# EFR32FG25A221F1920IM56 register map
Vendor: Silicon Labs; Series: EFR32; File version: B
Registers are 32-bit, read-write, reset 0x0 unless marked. A register's access mark holds for its fields unless they carry their own. Offsets are from the block's base; [hi:lo] are bit positions; {n}, {i} and the like mark numbered series; 'fields as' and 'values as' point back to an identical list.

## BUFC_NS — BUFC_NS Registers
Base 0x52000000
Same registers: BUFC_S 0x42000000
0x00 IPVERSION ro reset 0x3
0x04 EN
  [0] EN — Enable peripheral clock to this module
0x08 LPMODE
  [1:0] LPEN — Low power mode enable
{0xC+0x40*i} BUF{i}_CTRL (i=0..3)
  [2:0] SIZE — Buffer Size
    0=Sets Buffer size to 64 bytes; 1=Sets Buffer size to 128 bytes; 2=Sets Buffer size to 256 bytes; 3=Sets Buffer size to 512 bytes; 4=Sets Buffer size to 1024 bytes; 5=Sets Buffer size to 2048 bytes; 6=Sets Buffer size to 4096 bytes
{0x10+0x40*i} BUF{i}_ADDR reset 0x20000000 (i=0..3)
  [31:2] ADDR — Buffer Address
{0x14+0x40*i} BUF{i}_WRITEOFFSET (i=0..3)
  [12:0] WRITEOFFSET
{0x18+0x40*i} BUF{i}_READOFFSET (i=0..3)
  [12:0] READOFFSET
{0x20+0x40*i} BUF{i}_READDATA ro (i=0..3)
  [7:0] READDATA — Buffer Read Data
{0x24+0x40*i} BUF{i}_WRITEDATA wo (i=0..3)
  [7:0] WRITEDATA — Buffer Write Data
{0x28+0x40*i} BUF{i}_XWRITE wo (i=0..3)
  [7:0] XORWRITEDATA — Buffer XOR Write Data
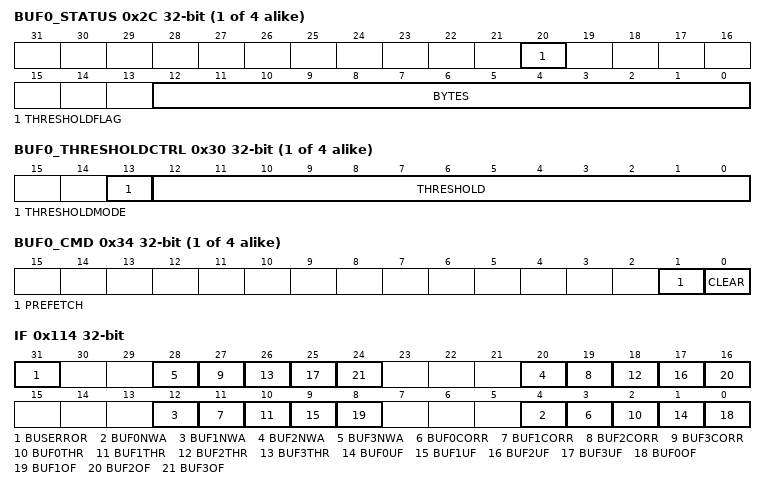
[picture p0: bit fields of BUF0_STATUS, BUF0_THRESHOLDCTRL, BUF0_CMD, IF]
{0x2C+0x40*i} BUF{i}_STATUS ro (i=0..3)
  [20] THRESHOLDFLAG — Buffer Threshold Flag
  [12:0] BYTES — Number of Bytes in the Buffer
{0x30+0x40*i} BUF{i}_THRESHOLDCTRL (i=0..3)
  [13] THRESHOLDMODE — Buffer Threshold Mode
    0=LARGER (THRESHOLDIF will be set if BYTES is larger than THRESHOLD); 1=LESSOREQUAL (THRESHOLDIF will be set if BYTES is less than or equal to THRESHOLD)
  [12:0] THRESHOLD — Buffer Threshold Value
{0x34+0x40*i} BUF{i}_CMD wo (i=0..3)
  [1] PREFETCH
  [0] CLEAR — Buffer Clear
{0x3C+0x40*i} BUF{i}_READDATA32 ro (i=0..3)
  [31:0] READDATA32 — Buffer Read Data
{0x40+0x40*i} BUF{i}_WRITEDATA32 wo (i=0..3)
  [31:0] WRITEDATA32 — Buffer Write Data
{0x44+0x40*i} BUF{i}_XWRITE32 wo (i=0..3)
  [31:0] XORWRITEDATA32 — Buffer XOR Write Data
0x114 IF
  [31] BUSERROR
  [8n+4] BUF{n}NWA (n=0..3) — Buffer {n} Not Word-Aligned
  [8n+3] BUF{n}CORR (n=0..3) — Buffer {n} Corrupt
  [8n+2] BUF{n}THR (n=0..3) — Buffer {n} Threshold Event
  [8n+1] BUF{n}UF (n=0..3) — Buffer {n} Underflow
  [8n] BUF{n}OF (n=0..3) — Buffer {n} Overflow
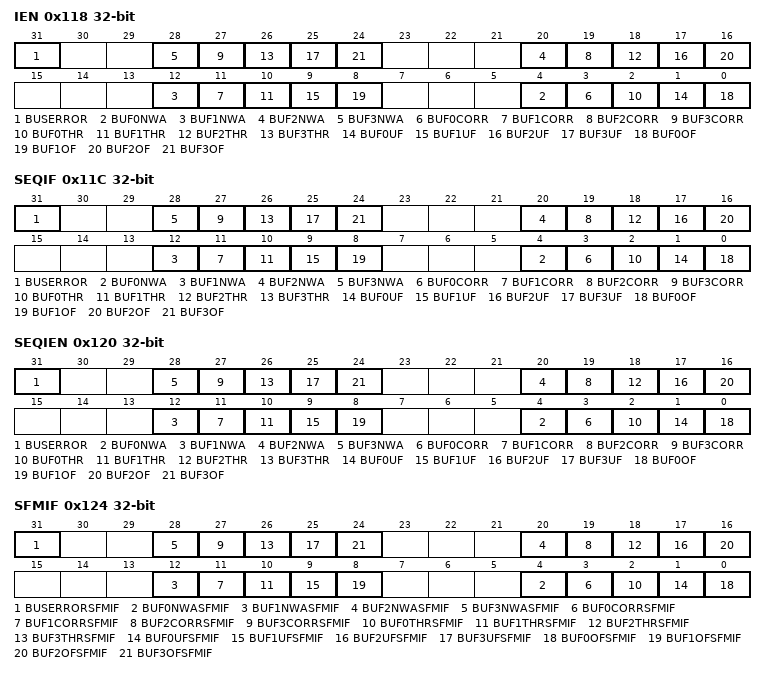
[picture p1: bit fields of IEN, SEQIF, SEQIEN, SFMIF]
0x118 IEN
  [31] BUSERROR — BUSERROR Interrupt Enable
  [8n+4] BUF{n}NWA (n=0..3) — BUF{n}NWA Interrupt Enable
  [8n+3] BUF{n}CORR (n=0..3) — BUF{n}CORR Interrupt Enable
  [8n+2] BUF{n}THR (n=0..3) — BUF{n}THR Interrupt Enable
  [8n+1] BUF{n}UF (n=0..3) — BUF{n}UF Interrupt Enable
  [8n] BUF{n}OF (n=0..3) — BUF{n}OF Interrupt Enable
0x11C SEQIF
  fields as IF
0x120 SEQIEN
  fields as IEN
0x124 SFMIF
  [31] BUSERRORSFMIF — Bus Error
  [8n+4] BUF{n}NWASFMIF (n=0..3) — Buffer {n} Not Word-Aligned
  [8n+3] BUF{n}CORRSFMIF (n=0..3) — Buffer {n} Corrupt
  [8n+2] BUF{n}THRSFMIF (n=0..3) — Buffer {n} Threshold Event
  [8n+1] BUF{n}UFSFMIF (n=0..3) — Buffer {n} Underflow
  [8n] BUF{n}OFSFMIF (n=0..3) — Buffer {n} Overflow
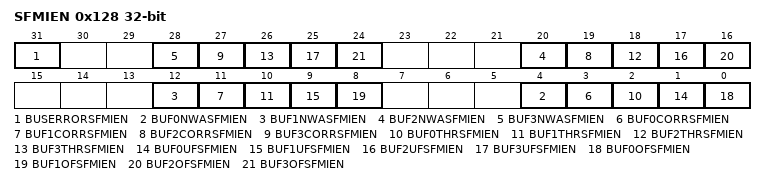
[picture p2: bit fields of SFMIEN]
0x128 SFMIEN
  [31] BUSERRORSFMIEN — BUSERROR Interrupt Enable
  [8n+4] BUF{n}NWASFMIEN (n=0..3) — BUF{n}NWA Interrupt Enable
  [8n+3] BUF{n}CORRSFMIEN (n=0..3) — BUF{n}CORR Interrupt Enable
  [8n+2] BUF{n}THRSFMIEN (n=0..3) — BUF{n}THR Interrupt Enable
  [8n+1] BUF{n}UFSFMIEN (n=0..3) — BUF{n}UF Interrupt Enable
  [8n] BUF{n}OFSFMIEN (n=0..3) — BUF{n}OF Interrupt Enable

## BURAM_NS — BURAM_NS Registers
Base 0x50080000
Same registers: BURAM_S 0x40080000
{0x0+4i} RET{i}_REG (i=0..31)
  [31:0] RETREG — Latch based Retention register

## BURTC_NS — BURTC_NS Registers
Base 0x5006C000
Same registers: BURTC_S 0x4006C000
0x00 IPVERSION ro reset 0x1
  [31:0] IPVERSION — IP Version ID
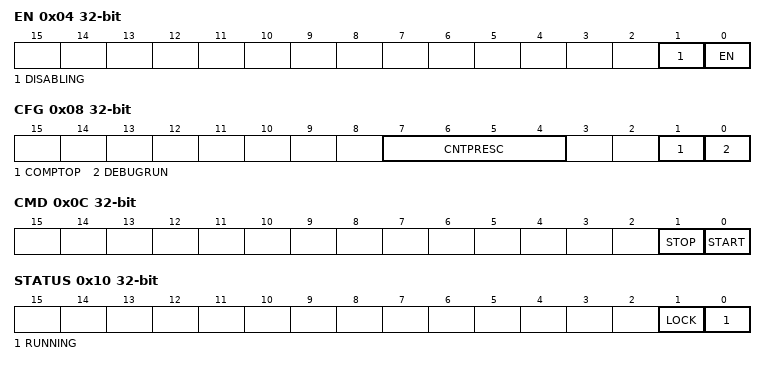
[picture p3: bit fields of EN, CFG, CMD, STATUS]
0x04 EN
  [1] DISABLING ro — Disablement busy status
  [0] EN — BURTC Enable
0x08 CFG
  [7:4] CNTPRESC — Counter prescaler value.
    0=DIV1 (CLK_CNT = (BURTC LF CLK)/1); 1=DIV2 (CLK_CNT = (BURTC LF CLK)/2); 2=DIV4 (CLK_CNT = (BURTC LF CLK)/4); 3=DIV8 (CLK_CNT = (BURTC LF CLK)/8); 4=DIV16 (CLK_CNT = (BURTC LF CLK)/16); 5=DIV32 (CLK_CNT = (BURTC LF CLK)/32); 6=DIV64 (CLK_CNT = (BURTC LF CLK)/64); 7=DIV128 (CLK_CNT = (BURTC LF CLK)/128); 8=DIV256 (CLK_CNT = (BURTC LF CLK)/256); 9=DIV512 (CLK_CNT = (BURTC LF CLK)/512); 10=DIV1024 (CLK_CNT = (BURTC LF CLK)/1024); 11=DIV2048 (CLK_CNT = (BURTC LF CLK)/2048); 12=DIV4096 (CLK_CNT = (BURTC LF CLK)/4096); 13=DIV8192 (CLK_CNT = (BURTC LF CLK)/8192); 14=DIV16384 (CLK_CNT = (BURTC LF CLK)/16384); 15=DIV32768 (CLK_CNT = (BURTC LF CLK)/32768)
  [1] COMPTOP — Compare Channel is Top Value
    0=DISABLE (The top value of the BURTC is 4294967295 (0xFFFFFFFF)); 1=ENABLE (The top value of the BURTC is given by COMP)
  [0] DEBUGRUN — Debug Mode Run Enable
    0=BURTC is frozen in debug mode; 1=BURTC is running in debug mode
0x0C CMD wo
  [1] STOP — Stop BURTC counter
  [0] START — Start BURTC counter
0x10 STATUS ro
  [1] LOCK — Configuration Lock Status
    0=UNLOCKED (All BURTC lockable registers are unlocked.); 1=LOCKED (All BURTC lockable registers are locked.)
  [0] RUNNING — BURTC running status
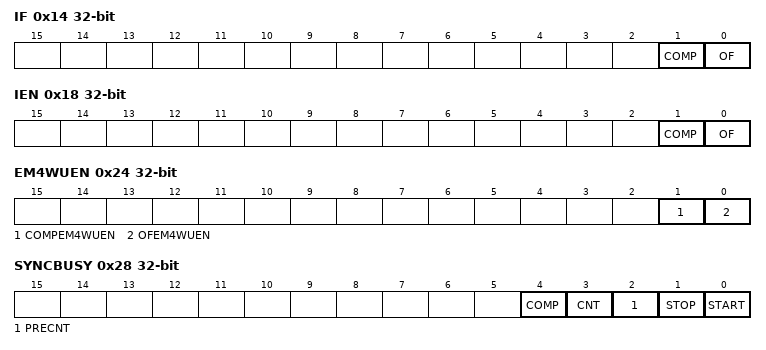
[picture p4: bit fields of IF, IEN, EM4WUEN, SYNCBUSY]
0x14 IF
  [1] COMP — Compare Match Interrupt Flag
  [0] OF — Overflow Interrupt Flag
0x18 IEN
  fields as IF
0x1C PRECNT
  [14:0] PRECNT — Pre-Counter Value
0x20 CNT
  [31:0] CNT — Counter Value
0x24 EM4WUEN
  [1] COMPEM4WUEN — Compare Match EM4 Wakeup Enable
  [0] OFEM4WUEN — Overflow EM4 Wakeup Enable
0x28 SYNCBUSY ro
  [4] COMP — Sync busy for COMP
  [3] CNT — Sync busy for CNT
  [2] PRECNT — Sync busy for PRECNT
  [1] STOP — Sync busy for STOP
  [0] START — Sync busy for START
0x2C LOCK wo reset 0xAEE8
  [15:0] LOCKKEY — Configuration Lock Key
    0xAEE8=UNLOCK (Write to unlock all BURTC lockable registers)
0x30 COMP
  [31:0] COMP — Compare Value
